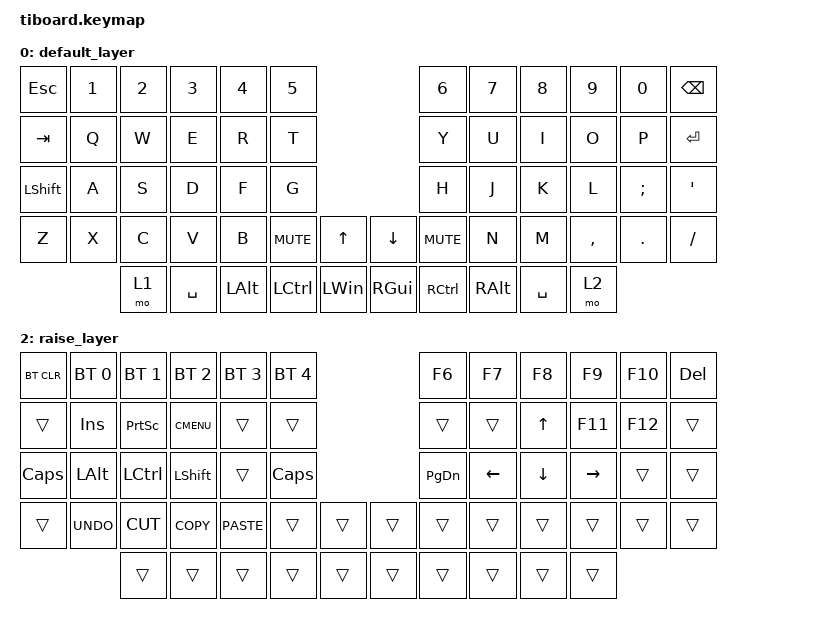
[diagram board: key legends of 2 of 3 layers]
/*
 * Copyright (c) 2020 The ZMK Contributors
 *
 * SPDX-License-Identifier: MIT
 */

#include <behaviors.dtsi>
#include <dt-bindings/zmk/keys.h>
#include <dt-bindings/zmk/bt.h>
#include <dt-bindings/zmk/rgb.h>
#include <dt-bindings/zmk/ext_power.h>



// // Enable mouse 启用鼠标

// #include <dt-bindings/zmk/mouse.h>
// #include <dt-bindings/zmk/mouse_settings.h>

// // Enable Mouse Keys 启用鼠标键

// #include "includes/mouse_keys.dtsi"
// #include <dt-bindings/zmk/bt.h>
// #include <dt-bindings/zmk/keys.h>
// #include <dt-bindings/zmk/rgb.h>

// 以下的代码用来降低旋转分辨率

&left_encoder {
    resolution = <4>;
};

&right_encoder {
    resolution = <4>;
};

/ {
    keymap {
        compatible = "zmk,keymap";

        default_layer {

            bindings = <
  &kp ESC  &kp N1  &kp N2     &kp N3    &kp N4      &kp N5                              &kp N6    &kp N7     &kp N8     &kp N9    &kp N0  &kp BACKSPACE
  &kp TAB   &kp Q   &kp W      &kp E     &kp R       &kp T                               &kp Y     &kp U      &kp I      &kp O     &kp P      &kp ENTER
&kp LSHFT   &kp A   &kp S      &kp D     &kp F       &kp G                               &kp H     &kp J      &kp K      &kp L  &kp SEMI        &kp SQT
    &kp Z   &kp X   &kp C      &kp V     &kp B  &kp C_MUTE        &kp UP  &kp DOWN  &kp C_MUTE     &kp N      &kp M  &kp COMMA   &kp DOT      &kp SLASH
                    &mo 1  &kp SPACE  &kp LALT   &kp LCTRL  &kp LEFT_WIN  &kp RGUI   &kp RCTRL  &kp RALT  &kp SPACE      &mo 2
            >;

            sensor-bindings = <&inc_dec_kp LEFT RIGHT &inc_dec_kp C_VOL_DN C_VOL_UP>;
        };

        lower_layer {
            bindings = <
&trans     &kp F1     &kp F2     &kp F3       &kp F4    &kp F5                              &rgb_ug RGB_EFF    &kp KP_NUMBER_7  &kp KP_NUMBER_8  &kp KP_NUMBER_9  &kp MINUS         &kp EQUAL
&kp GRAVE  &kp N1     &kp N2     &kp N3       &kp N4    &kp N5                              &ext_power EP_TOG  &kp KP_NUMBER_4  &kp KP_NUMBER_5  &kp KP_NUMBER_6  &kp LEFT_BRACKET  &trans
&trans     &kp EXCL   &kp AT     &kp HASH     &kp DLLR  &kp PRCNT                           &bt BT_CLR         &kp KP_NUMBER_1  &kp KP_NUMBER_2  &kp KP_NUMBER_3  &kp RBKT          &kp PIPE
&trans     &kp EQUAL  &kp MINUS  &kp KP_PLUS  &kp LBRC  &kp RBRC   &trans  &rgb_ug RGB_BRI  &rgb_ug RGB_TOG    &bt BT_SEL 0     &bt BT_SEL 1     &kp KP_NUMBER_0  &trans            &bootloader
                      &trans     &trans       &trans    &trans     &trans  &trans           &bt BT_SEL 2       &rgb_ug RGB_BRD  &trans
            >;

            sensor-bindings = <&inc_dec_kp C_VOL_UP C_VOL_DN &inc_dec_kp PG_UP PG_DN>;
        };

        raise_layer {
            bindings = <
&bt BT_CLR    &bt BT_SEL 0  &bt BT_SEL 1  &bt BT_SEL 2  &bt BT_SEL 3  &bt BT_SEL 4                  &kp F6     &kp F7    &kp F8    &kp F9     &kp F10  &kp DEL
&trans        &kp INS       &kp PSCRN     &kp K_CMENU   &trans        &trans                        &trans     &trans    &kp UP    &kp F11    &kp F12  &trans
&kp CAPSLOCK  &kp LALT      &kp LCTRL     &kp LSHFT     &trans        &kp CLCK                      &kp PG_DN  &kp LEFT  &kp DOWN  &kp RIGHT  &trans   &trans
&trans        &kp K_UNDO    &kp K_CUT     &kp K_COPY    &kp K_PASTE   &trans        &trans  &trans  &trans     &trans    &trans    &trans     &trans   &trans
                            &trans        &trans        &trans        &trans        &trans  &trans  &trans     &trans    &trans    &trans
            >;

            sensor-bindings = <&inc_dec_kp C_VOL_UP C_VOL_DN &inc_dec_kp PG_UP PG_DN>;
        };
    };
};
